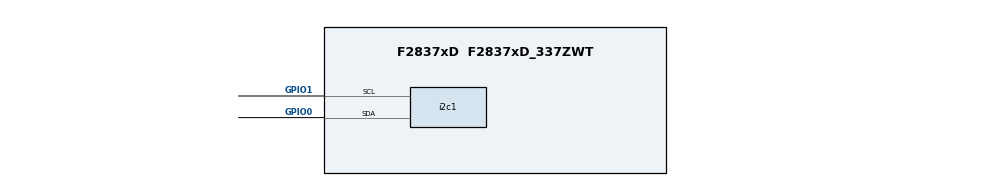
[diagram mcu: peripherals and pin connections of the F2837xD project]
/**
 * @cliArgs --device "F2837xD" --package "F2837xD_337ZWT" --part "F2837xD_337ZWT" --context "CPU1" --product "C2000WARE@4.03.00.00"
 * @versions {"tool":"1.16.1+2960"}
 */

/**
 * Import the modules used in this configuration.
 */
const i2c  = scripting.addModule("/driverlib/i2c.js", {}, false);
const i2c1 = i2c.addInstance();

/**
 * Write custom configuration values to the imported modules.
 */
i2c1.$name              = "MPU6050";
i2c1.bitCount           = "I2C_BITCOUNT_8";
i2c1.targetAddress      = 0x68;
i2c1.useFifo            = false;
i2c1.enabledInterrupts  = ["I2C_INT_REG_ACCESS_RDY","I2C_INT_RX_DATA_RDY","I2C_INT_STOP_CONDITION","I2C_INT_TX_DATA_RDY"];
i2c1.emulationMode      = "I2C_EMULATION_FREE_RUN";
i2c1.bitRate            = 1000;
i2c1.i2c.$assign        = "I2CA";
i2c1.i2c.sdaPin.$assign = "GPIO0";
i2c1.i2c.sclPin.$assign = "GPIO1";
